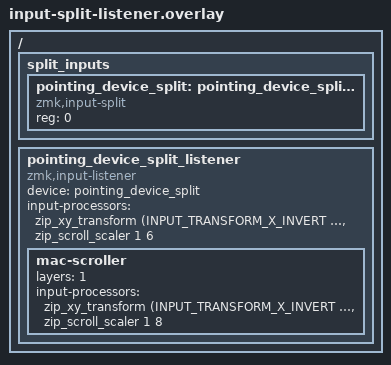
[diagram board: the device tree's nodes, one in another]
/{
    split_inputs {
        #address-cells = <1>;
        #size-cells = <0>;

        pointing_device_split: pointing_device_split@0 {
            compatible = "zmk,input-split";
            reg = <0>;
        };
    };

    pointing_device_split_listener: pointing_device_split_listener {
        compatible = "zmk,input-listener";
        device = <&pointing_device_split>;
        status = "okay";
        // Windows/base path: same speed as the previous Mac setting.
        input-processors =
            <&zip_xy_transform (INPUT_TRANSFORM_X_INVERT | INPUT_TRANSFORM_Y_INVERT)>,
            <&zip_scroll_scaler 1 6>;

        mac-scroller {
            // L1 stays active under Mac's momentary layers and Bluetooth management.
            // Override the base path: 25% slower than the previous Mac setting.
            layers = <1>;
            input-processors =
                <&zip_xy_transform (INPUT_TRANSFORM_X_INVERT | INPUT_TRANSFORM_Y_INVERT)>,
                <&zip_scroll_scaler 1 8>;
        };
     };
};
